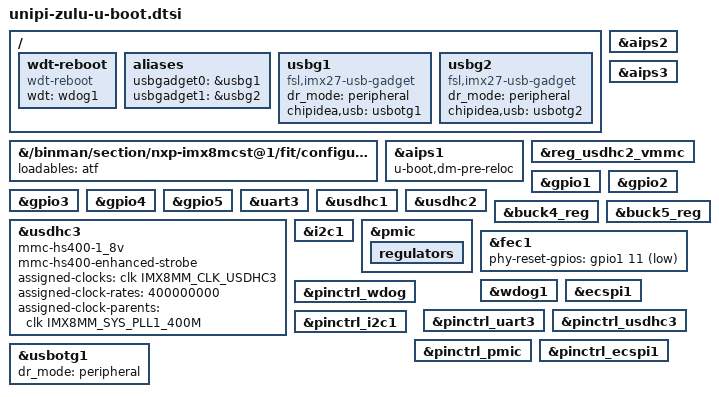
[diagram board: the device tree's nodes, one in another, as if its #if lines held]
// SPDX-License-Identifier: GPL-2.0+
/*
 * (C) Copyright 2023 Unipi Technology s.r.o.
 */

#include "imx8mm-u-boot.dtsi"
/ {

	wdt-reboot {
		compatible = "wdt-reboot";
		wdt = <&wdog1>;
		bootph-pre-ram;
	};

	aliases {
		usbgadget0 = &usbg1;
		usbgadget1 = &usbg2;
	};

	usbg1: usbg1 {
		compatible = "fsl,imx27-usb-gadget";
		dr_mode = "peripheral";
		chipidea,usb = <&usbotg1>;
		status = "okay";
	};

	usbg2: usbg2 {
		compatible = "fsl,imx27-usb-gadget";
		dr_mode = "peripheral";
		chipidea,usb = <&usbotg2>;
		status = "okay";
	};

};

#if !IS_ENABLED(CONFIG_OPTEE)
/delete-node/ &binman_fip;
/delete-node/ &tee;
#if IS_ENABLED(CONFIG_IMX_HAB)
&{/binman/section/nxp-imx8mcst@1/fit/configurations/@config-SEQ} {
	loadables = "atf";
};
#else
&{/binman/section/fit/configurations/@config-SEQ} {
	loadables = "atf";
};
#endif
#endif

&aips1 {
	bootph-pre-ram;
	u-boot,dm-pre-reloc;
};

&aips2 {
	bootph-pre-ram;
};

&aips3 {
	bootph-pre-ram;
};

&reg_usdhc2_vmmc {
	bootph-pre-ram;
};

&gpio1 {
	bootph-pre-ram;
};

&gpio2 {
	bootph-pre-ram;
};

&gpio3 {
	bootph-pre-ram;
};

&gpio4 {
	bootph-pre-ram;
};

&gpio5 {
	bootph-pre-ram;
};

&uart3 {
	bootph-pre-ram;
	bootph-all;
};

/* usdhc1 and usdhc2 must be pre-ram hav stable MMC indexes (boot form MMC2) */
&usdhc1 {
	bootph-pre-ram;
};

&usdhc2 {
	bootph-pre-ram;
};

&usdhc3 {
	bootph-pre-ram;
	mmc-hs400-1_8v;
	mmc-hs400-enhanced-strobe;
	assigned-clocks = <&clk IMX8MM_CLK_USDHC3>;
	assigned-clock-rates = <400000000>;
	assigned-clock-parents = <&clk IMX8MM_SYS_PLL1_400M>;
};

&buck4_reg {
	bootph-pre-ram;
};

&buck5_reg {
	bootph-pre-ram;
};

&i2c1 {
	bootph-pre-ram;
};

&pmic {
	bootph-pre-ram;

	regulators {
		bootph-pre-ram;
	};
};

&fec1 {
	phy-reset-gpios = <&gpio1 11 GPIO_ACTIVE_LOW>;
};

&wdog1 {
	bootph-pre-ram;
};

&ecspi1 {
	bootph-pre-ram;
};

&pinctrl_wdog {
	bootph-pre-ram;
};

&pinctrl_uart3 {
	bootph-pre-ram;
	bootph-all;
};

&pinctrl_usdhc3 {
	bootph-pre-ram;
};

&pinctrl_i2c1 {
	bootph-pre-ram;
};

&pinctrl_pmic {
	bootph-pre-ram;
};

&pinctrl_ecspi1 {
	bootph-pre-ram;
};

&usbotg1 {
	dr_mode = "peripheral";
	bootph-pre-ram;
};

